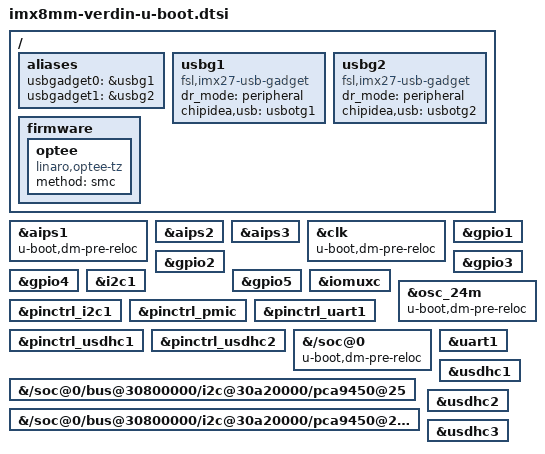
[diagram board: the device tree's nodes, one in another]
// SPDX-License-Identifier: GPL-2.0+ OR MIT
/*
 * Copyright 2020 Toradex
 */

/ {

	aliases {
		usbgadget0 = &usbg1;
		usbgadget1 = &usbg2;
	};

	usbg1: usbg1 {
		compatible = "fsl,imx27-usb-gadget";
		dr_mode = "peripheral";
		chipidea,usb = <&usbotg1>;
		status = "okay";
	};

	usbg2: usbg2 {
		compatible = "fsl,imx27-usb-gadget";
		dr_mode = "peripheral";
		chipidea,usb = <&usbotg2>;
		status = "okay";
	};

	firmware {
		optee {
			compatible = "linaro,optee-tz";
			method = "smc";
		};
	};
};

&aips1 {
	u-boot,dm-spl;
	u-boot,dm-pre-reloc;
};

&aips2 {
	u-boot,dm-spl;
};

&aips3 {
	u-boot,dm-spl;
};

&clk {
	u-boot,dm-spl;
	u-boot,dm-pre-reloc;
	/delete-property/ assigned-clocks;
	/delete-property/ assigned-clock-parents;
	/delete-property/ assigned-clock-rates;
};

&gpio1 {
	u-boot,dm-spl;
};

&gpio2 {
	u-boot,dm-spl;
};

&gpio3 {
	u-boot,dm-spl;
};

&gpio4 {
	u-boot,dm-spl;
};

&gpio5 {
	u-boot,dm-spl;
};

&i2c1 {
	u-boot,dm-spl;
};

&iomuxc {
	u-boot,dm-spl;
};

&osc_24m {
	u-boot,dm-spl;
	u-boot,dm-pre-reloc;
};

&pinctrl_i2c1 {
	u-boot,dm-spl;
};

&pinctrl_pmic {
	u-boot,dm-spl;
};

&pinctrl_uart1 {
	u-boot,dm-spl;
};

&pinctrl_usdhc1 {
	u-boot,dm-spl;
};

&pinctrl_usdhc2 {
	u-boot,dm-spl;
};

&{/soc@0} {
	u-boot,dm-pre-reloc;
	u-boot,dm-spl;
};

&{/soc@0/bus@30800000/i2c@30a20000/pca9450@25} {
	u-boot,dm-spl;
};

&{/soc@0/bus@30800000/i2c@30a20000/pca9450@25/regulators} {
	u-boot,dm-spl;
};

&uart1 {
	u-boot,dm-spl;
};

&usdhc1 {
	u-boot,dm-spl;
};

&usdhc2 {
	u-boot,dm-spl;
};

&usdhc3 {
	u-boot,dm-spl;
};
